# STM32L4x1 register map
File version: 1.0
Registers are 32-bit, read-write, reset 0x0 unless marked. A register's access mark holds for its fields unless they carry their own. Offsets are from the block's base; [hi:lo] are bit positions; {n}, {i} and the like mark numbered series; 'fields as' and 'values as' point back to an identical list.

## QUADSPI — QuadSPI interface
Base 0xA0001000
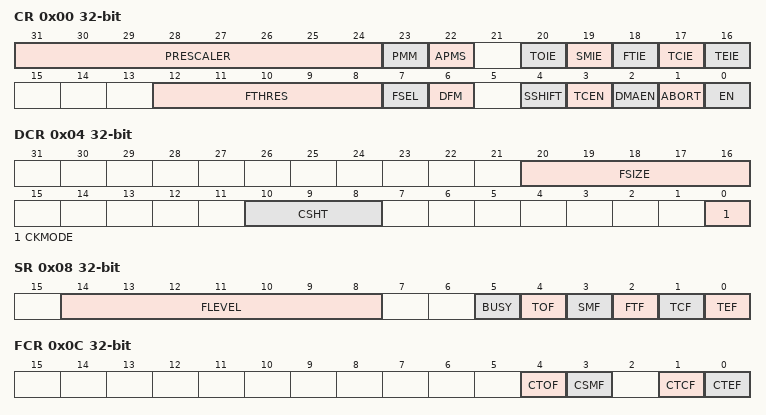
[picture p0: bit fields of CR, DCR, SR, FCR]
0x00 CR — control register
  [31:24] PRESCALER — Clock prescaler
  [23] PMM — Polling match mode
  [22] APMS — Automatic poll mode stop
  [20] TOIE — TimeOut interrupt enable
  [19] SMIE — Status match interrupt enable
  [18] FTIE — FIFO threshold interrupt enable
  [17] TCIE — Transfer complete interrupt enable
  [16] TEIE — Transfer error interrupt enable
  [12:8] FTHRES — IFO threshold level
  [7] FSEL — FLASH memory selection
  [6] DFM — Dual-flash mode
  [4] SSHIFT — Sample shift
  [3] TCEN — Timeout counter enable
  [2] DMAEN — DMA enable
  [1] ABORT — Abort request
  [0] EN — Enable
0x04 DCR — device configuration register
  [20:16] FSIZE — FLASH memory size
  [10:8] CSHT — Chip select high time
  [0] CKMODE — Mode 0 / mode 3
0x08 SR ro — status register
  [14:8] FLEVEL — FIFO level
  [5] BUSY
  [4] TOF — Timeout flag
  [3] SMF — Status match flag
  [2] FTF — FIFO threshold flag
  [1] TCF — Transfer complete flag
  [0] TEF — Transfer error flag
0x0C FCR — flag clear register
  [4] CTOF — Clear timeout flag
  [3] CSMF — Clear status match flag
  [1] CTCF — Clear transfer complete flag
  [0] CTEF — Clear transfer error flag
0x10 DLR — data length register
  [31:0] DL — Data length
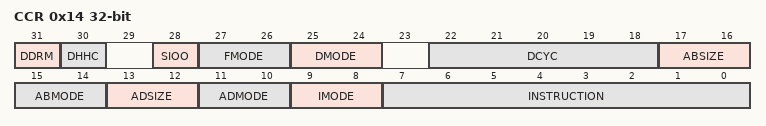
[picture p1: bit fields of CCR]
0x14 CCR — communication configuration register
  [31] DDRM — Double data rate mode
  [30] DHHC — DDR hold half cycle
  [28] SIOO — Send instruction only once mode
  [27:26] FMODE — Functional mode
  [25:24] DMODE — Data mode
  [22:18] DCYC — Number of dummy cycles
  [17:16] ABSIZE — Alternate bytes size
  [15:14] ABMODE — Alternate bytes mode
  [13:12] ADSIZE — Address size
  [11:10] ADMODE — Address mode
  [9:8] IMODE — Instruction mode
  [7:0] INSTRUCTION
0x18 AR — address register
  [31:0] ADDRESS
0x1C ABR
  [31:0] ALTERNATE
0x20 DR — data register
  [31:0] DATA
0x24 PSMKR — polling status mask register
  [31:0] MASK — Status mask
0x28 PSMAR — polling status match register
  [31:0] MATCH — Status match
0x2C PIR — polling interval register
  [15:0] INTERVAL — Polling interval
0x30 LPTR — low-power timeout register
  [15:0] TIMEOUT — Timeout period

## FMC — Flexible memory controller
Base 0xA0000000
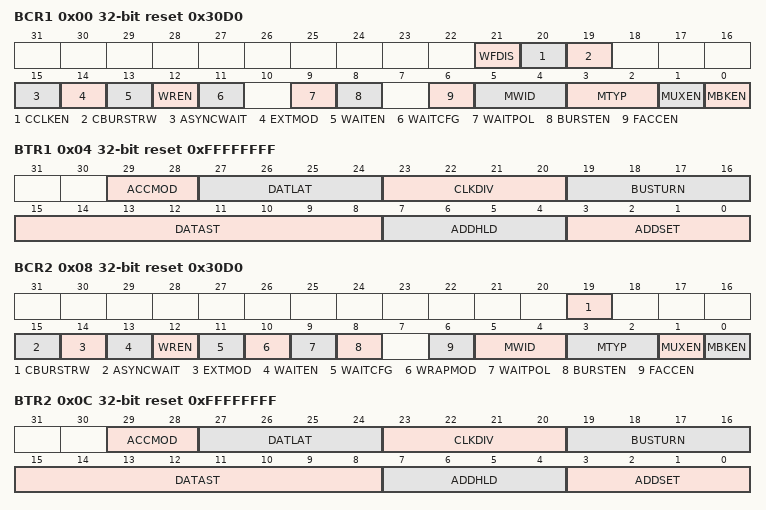
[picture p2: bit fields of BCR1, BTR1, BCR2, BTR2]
0x00 BCR1 reset 0x30D0 — SRAM/NOR-Flash chip-select control register 1
  [21] WFDIS — Write FIFO Disable
  [20] CCLKEN
  [19] CBURSTRW
  [15] ASYNCWAIT
  [14] EXTMOD
  [13] WAITEN
  [12] WREN
  [11] WAITCFG
  [9] WAITPOL
  [8] BURSTEN
  [6] FACCEN
  [5:4] MWID
  [3:2] MTYP
  [1] MUXEN
  [0] MBKEN
0x04 BTR1 reset 0xFFFFFFFF — SRAM/NOR-Flash chip-select timing register 1
  [29:28] ACCMOD, [27:24] DATLAT, [23:20] CLKDIV, [19:16] BUSTURN, [15:8] DATAST, [7:4] ADDHLD, [3:0] ADDSET
0x08 BCR2 reset 0x30D0 — SRAM/NOR-Flash chip-select control register 2
  [19] CBURSTRW, [15] ASYNCWAIT, [14] EXTMOD, [13] WAITEN, [12] WREN, [11] WAITCFG, [10] WRAPMOD, [9] WAITPOL, [8] BURSTEN, [6] FACCEN, [5:4] MWID, [3:2] MTYP, [1] MUXEN, [0] MBKEN
0x0C BTR2 reset 0xFFFFFFFF — SRAM/NOR-Flash chip-select timing register 2
  fields as BTR1
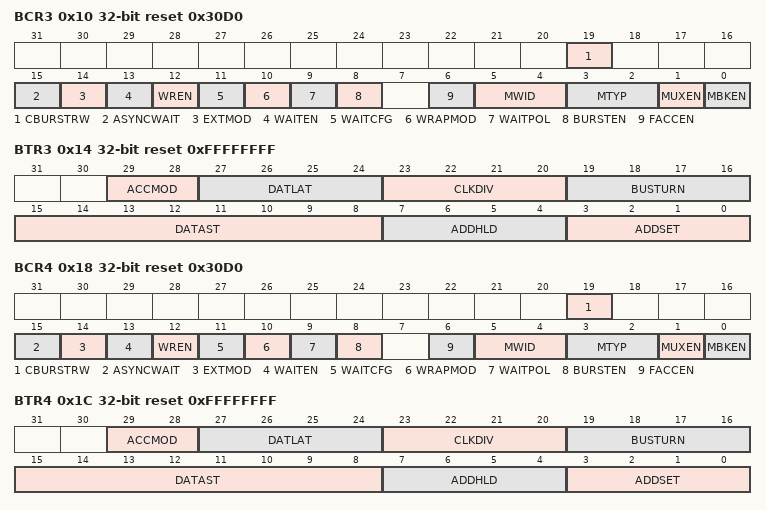
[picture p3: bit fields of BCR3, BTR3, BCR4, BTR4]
0x10 BCR3 reset 0x30D0 — SRAM/NOR-Flash chip-select control register 3
  fields as BCR2
0x14 BTR3 reset 0xFFFFFFFF — SRAM/NOR-Flash chip-select timing register 3
  fields as BTR1
0x18 BCR4 reset 0x30D0 — SRAM/NOR-Flash chip-select control register 4
  fields as BCR2
0x1C BTR4 reset 0xFFFFFFFF — SRAM/NOR-Flash chip-select timing register 4
  fields as BTR1
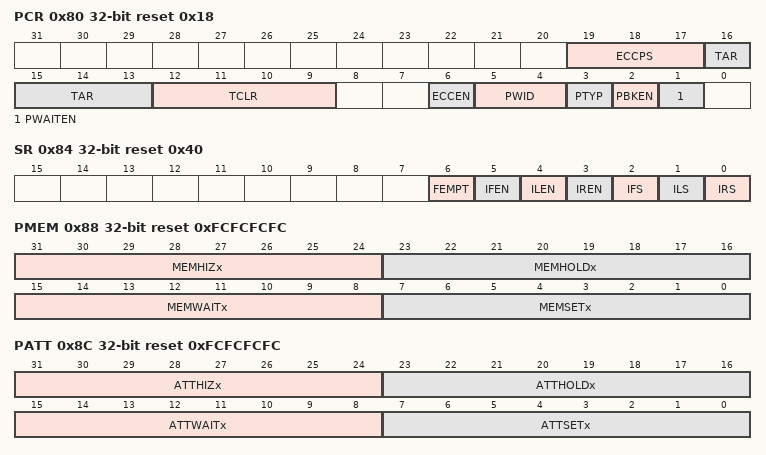
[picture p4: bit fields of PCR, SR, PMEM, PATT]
0x80 PCR reset 0x18 — PC Card/NAND Flash control register 3
  [19:17] ECCPS, [16:13] TAR, [12:9] TCLR, [6] ECCEN, [5:4] PWID, [3] PTYP, [2] PBKEN, [1] PWAITEN
0x84 SR access per field reset 0x40 — FIFO status and interrupt register 3
  [6] FEMPT ro, [5] IFEN rw, [4] ILEN rw, [3] IREN rw, [2] IFS rw, [1] ILS rw, [0] IRS rw
0x88 PMEM reset 0xFCFCFCFC — Common memory space timing register 3
  [31:24] MEMHIZx, [23:16] MEMHOLDx, [15:8] MEMWAITx, [7:0] MEMSETx
0x8C PATT reset 0xFCFCFCFC — Attribute memory space timing register 3
  [31:24] ATTHIZx, [23:16] ATTHOLDx, [15:8] ATTWAITx, [7:0] ATTSETx
0x94 ECCR ro — ECC result register 3
  [31:0] ECCx
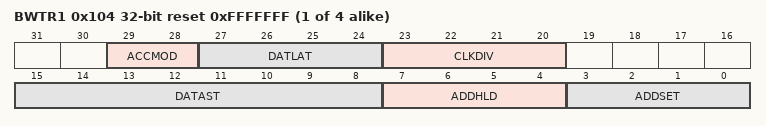
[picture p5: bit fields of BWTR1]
{0xFC+8i} BWTR{i} reset 0xFFFFFFF (i=1..4) — SRAM/NOR-Flash write timing registers {i}
  [29:28] ACCMOD, [27:24] DATLAT, [23:20] CLKDIV, [15:8] DATAST, [7:4] ADDHLD, [3:0] ADDSET

## ADC123_Common — Analog-to-Digital Converter
Base 0x50040300
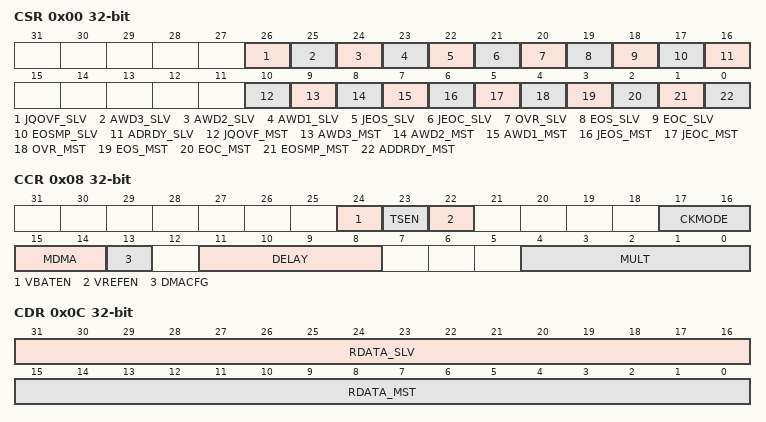
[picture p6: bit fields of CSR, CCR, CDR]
0x00 CSR ro — ADC Common status register
  [26] JQOVF_SLV — Injected Context Queue Overflow flag of the slave ADC
  [25] AWD3_SLV — Analog watchdog 3 flag of the slave ADC
  [24] AWD2_SLV — Analog watchdog 2 flag of the slave ADC
  [23] AWD1_SLV — Analog watchdog 1 flag of the slave ADC
  [22] JEOS_SLV — End of injected sequence flag of the slave ADC
  [21] JEOC_SLV — End of injected conversion flag of the slave ADC
  [20] OVR_SLV — Overrun flag of the slave ADC
  [19] EOS_SLV — End of regular sequence flag of the slave ADC
  [18] EOC_SLV — End of regular conversion of the slave ADC
  [17] EOSMP_SLV
  [16] ADRDY_SLV
  [10] JQOVF_MST
  [9] AWD3_MST
  [8] AWD2_MST
  [7] AWD1_MST
  [6] JEOS_MST
  [5] JEOC_MST
  [4] OVR_MST
  [3] EOS_MST
  [2] EOC_MST
  [1] EOSMP_MST
  [0] ADDRDY_MST
0x08 CCR — ADC common control register
  [24] VBATEN — VBAT enable
  [23] TSEN — Temperature sensor enable
  [22] VREFEN — VREFINT enable
  [17:16] CKMODE — ADC clock mode
  [15:14] MDMA — Direct memory access mode for multi ADC mode
  [13] DMACFG — DMA configuration (for multi-ADC mode)
  [11:8] DELAY — Delay between 2 sampling phases
  [4:0] MULT — Multi ADC mode selection
0x0C CDR ro — ADC common regular data register for dual and triple modes
  [31:16] RDATA_SLV — Regular data of the slave ADC
  [15:0] RDATA_MST — Regular data of the master ADC
